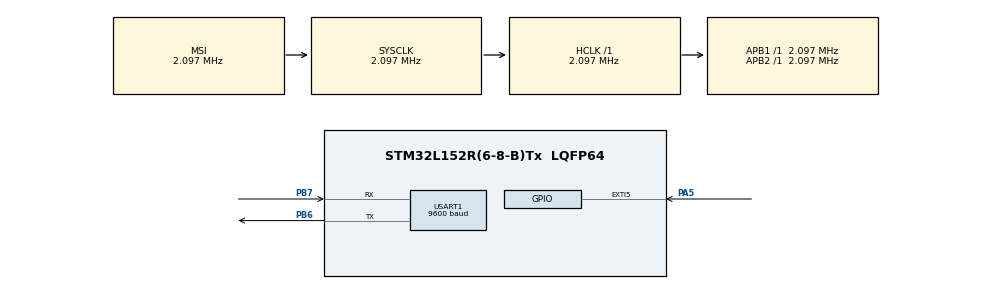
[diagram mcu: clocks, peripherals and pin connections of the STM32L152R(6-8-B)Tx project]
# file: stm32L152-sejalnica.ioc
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Mcu.Family=STM32L1
Mcu.Name=STM32L152R(6-8-B)Tx
Mcu.Package=LQFP64
NVIC.EXTI9_5_IRQn=true\:0\:0\:false\:false\:true\:true
NVIC.PriorityGroup=NVIC_PRIORITYGROUP_4
NVIC.TIM2_IRQn=true\:0\:0\:false\:false\:true\:true
NVIC.USART1_IRQn=true\:0\:0\:false\:false\:true\:true
PA5.GPIO_PuPd=GPIO_PULLUP
PA5.Signal=GPXTI5
PB6.Mode=Asynchronous
PB6.Signal=USART1_TX
PB7.Mode=Asynchronous
PB7.Signal=USART1_RX
ProjectManager.HeapSize=0x200
ProjectManager.StackSize=0x400
ProjectManager.TargetToolchain=SW4STM32
RCC.AHBFreq_Value=2097000
RCC.APB1Freq_Value=2097000
RCC.APB2Freq_Value=2097000
RCC.HSE_VALUE=24000000
RCC.HSI_VALUE=16000000
RCC.LSE_VALUE=32768
RCC.MSI_VALUE=2097000
RCC.SYSCLKFreq_VALUE=2097000
RCC.VCOOutputFreq_Value=48000000
TIM2.Period=5999
TIM2.Prescaler=20970
USART1.BaudRate=9600
USART1.VirtualMode=VM_ASYNC
VP_TIM2_VS_ClockSourceINT.Mode=Internal
board=stm32L152-sejalnica

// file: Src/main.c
/**
  ******************************************************************************
  * File Name          : main.c
  * Description        : Main program body
  ******************************************************************************
  *
  * COPYRIGHT(c) 2017 STMicroelectronics
  *
  * Redistribution and use in source and binary forms, with or without modification,
  * are permitted provided that the following conditions are met:
  *   1. Redistributions of source code must retain the above copyright notice,
  *      this list of conditions and the following disclaimer.
  *   2. Redistributions in binary form must reproduce the above copyright notice,
  *      this list of conditions and the following disclaimer in the documentation
  *      and/or other materials provided with the distribution.
  *   3. Neither the name of STMicroelectronics nor the names of its contributors
  *      may be used to endorse or promote products derived from this software
  *      without specific prior written permission.
  *
  * THIS SOFTWARE IS PROVIDED BY THE COPYRIGHT HOLDERS AND CONTRIBUTORS "AS IS"
  * AND ANY EXPRESS OR IMPLIED WARRANTIES, INCLUDING, BUT NOT LIMITED TO, THE
  * IMPLIED WARRANTIES OF MERCHANTABILITY AND FITNESS FOR A PARTICULAR PURPOSE ARE
  * DISCLAIMED. IN NO EVENT SHALL THE COPYRIGHT HOLDER OR CONTRIBUTORS BE LIABLE
  * FOR ANY DIRECT, INDIRECT, INCIDENTAL, SPECIAL, EXEMPLARY, OR CONSEQUENTIAL
  * DAMAGES (INCLUDING, BUT NOT LIMITED TO, PROCUREMENT OF SUBSTITUTE GOODS OR
  * SERVICES; LOSS OF USE, DATA, OR PROFITS; OR BUSINESS INTERRUPTION) HOWEVER
  * CAUSED AND ON ANY THEORY OF LIABILITY, WHETHER IN CONTRACT, STRICT LIABILITY,
  * OR TORT (INCLUDING NEGLIGENCE OR OTHERWISE) ARISING IN ANY WAY OUT OF THE USE
  * OF THIS SOFTWARE, EVEN IF ADVISED OF THE POSSIBILITY OF SUCH DAMAGE.
  *
  ******************************************************************************
  */
#include "main.h"
#include "stm32l1xx_hal.h"

/* USER CODE BEGIN Includes */
#include "stm32l152c_discovery.h"
#include "stm32l152c_discovery_glass_lcd.h"

/* USER CODE END Includes */

TIM_HandleTypeDef htim2;

UART_HandleTypeDef huart1;

/* USER CODE BEGIN PV */
/* Private variables ---------------------------------------------------------*/
int stevec=0;
int cas=0;
char data_tx[10];
char data_rx[2];
int len;
int overflow=0;
float sirina=3.0;//3=sirina sejalnice
float obseg;
float povrsina;
char* stevka_tmp;
char lcd_text[6];
/* USER CODE END PV */

void SystemClock_Config(void);
void Error_Handler(void);
static void MX_GPIO_Init(void);
static void MX_TIM2_Init(void);
static void MX_USART1_UART_Init(void);

/* USER CODE BEGIN PFP */
/* Private function prototypes -----------------------------------------------*/

char *substring(int i,int j,char *ch)
{
    int n,k=0;
    char *ch1;
    ch1=(char*)malloc((j-i+1)*1);
    n=j-i+1;

    while(k<n)
    {
        ch1[k]=ch[i];
        i++;k++;
    }
    return (char *)ch1;
}

float area(int counter){
		return (float)counter/4100;
}

float speed(float time, float circum){
  return (float)(circum/time)*1000;
}

void display(int counter, int mode){
	if (counter<50){
		sprintf(lcd_text, "%d",counter);
		BSP_LCD_GLASS_Clear();
		BSP_LCD_GLASS_DisplayString((uint8_t*)lcd_text);
	}
	else{
		if( counter%5 == 0 ){
		      sprintf(lcd_text, "%2.3f",area(counter));
		      BSP_LCD_GLASS_Clear();
		      BSP_LCD_GLASS_DisplayString((uint8_t*)lcd_text);
		}
		if (mode==1){
		      sprintf(lcd_text, "%2.3f",area(counter));
		      BSP_LCD_GLASS_Clear();
		      BSP_LCD_GLASS_DisplayString((uint8_t*)lcd_text);
		}
	}
	return;
}

void send_uart(int counter, int time){
	if (counter<50){
		if (time==0){
			sprintf(data_tx, "#%d-0~",stevec);
		}
		else{
			sprintf(data_tx, "#%d-%2.1f~",stevec, speed((float)time, obseg));
		}
	}
	else{
		if (time==0){
			sprintf(data_tx, "#%.4f-0~",area(stevec));
		}
		else{
			sprintf(data_tx, "#%.4f-%2.1f~",area(stevec), speed((float)time, obseg));
		}
	}
	len=strlen(data_tx);
	HAL_UART_Transmit( &huart1, data_tx, len, 100);
	return;

}

//ineruptna rutina za 'magnetni' stik na A5-GND
void HAL_GPIO_EXTI_Callback(uint16_t GPIO_Pin){
	stevec++;
  if (overflow!=0){
    cas=0;
    overflow=0;
  }
  else{
    cas = TIM2->CNT;
  }
  TIM2->CNT=0;

  send_uart(stevec,cas);
  display(stevec,0);
}

  /**
* @brief This function handles TIM2 global interrupt.
*/
void TIM2_IRQHandler(void)
{
  /* USER CODE BEGIN TIM2_IRQn 0 */

  TIM2->SR &=~TIM_SR_UIF;
  overflow++;
  send_uart(stevec,0);
  display(stevec,0);

  /* USER CODE END TIM2_IRQn 0 */
  //HAL_TIM_IRQHandler(&htim2);
  /* USER CODE BEGIN TIM2_IRQn 1 */

  /* USER CODE END TIM2_IRQn 1 */
}

//variables need to be declared at the beginning for USART
char Rx_indx, Rx_data[6], Rx_Buffer[20], Transfer_cplt;
int vred;
//Interrupt callback routine for USART receive

void HAL_UART_RxCpltCallback(UART_HandleTypeDef *huart)
{
	uint8_t i;
	if (huart->Instance == USART1)	//current UART
		{
		if (Rx_indx==0) {for (i=0;i<20;i++) Rx_Buffer[i]=0;}	//clear Rx_Buffer before receiving new data
                  if (Rx_data[0]!=33)	//if received data different from ascii 33 (!)
                          {
                          Rx_Buffer[Rx_indx++]=Rx_data[0];	//add data to Rx_Buffer

                          }
                  else			//if received data = 13
                          {
                          Rx_indx=0;
                          Transfer_cplt=1;//transfer complete, data is ready to read
                          if (Rx_Buffer[0]==35) //35=#=nastavljanje dolzine
                          {
                            stevka_tmp=substring(1,sizeof(Rx_Buffer),Rx_Buffer);
                            stevec=atoi(stevka_tmp);
                            sprintf(data_tx, "-%d~",stevec);
                            len=strlen(data_tx);
                            HAL_UART_Transmit( &huart1, (uint8_t*)data_tx , len, 100);
                            }

                          if (Rx_Buffer[0]==36) //36=$=refresh button
                          {
                            display(stevec,1);
                            send_uart(stevec,0);
                            }
                          }
                  HAL_UART_Receive_IT(&huart1, Rx_data, 1);	//activate UART receive interrupt every time
		}

}
/* USER CODE END PFP */

int main(void)
{

  /* USER CODE BEGIN 1 */
	obseg=100/41/sirina;
  /* USER CODE END 1 */

  /* MCU Configuration----------------------------------------------------------*/

  /* Reset of all peripherals, Initializes the Flash interface and the Systick. */
  HAL_Init();

  /* Configure the system clock */
  SystemClock_Config();

  /* Initialize all configured peripherals */
  //A5-GND
  MX_GPIO_Init();

  MX_TIM2_Init();
  /* pomen pinov na plosci:
  TX:B6
  RX:B7
  povezava na companion device:
  tx->B7
  rx->B6
  */
  MX_USART1_UART_Init();

  BSP_LCD_GLASS_Init();

  /* USER CODE BEGIN 2 */
  HAL_TIM_Base_Start_IT(&htim2); //zaceek interupta za timer
  TIM2->CR1 |= 0x0001;

  HAL_UART_Receive_IT(&huart1, (uint8_t*)Rx_data, 1); //start inerupta za uart
  /* USER CODE END 2 */

  /* Infinite loop */
   while (1)
  {

  }

}

/** System Clock Configuration
*/
void SystemClock_Config(void)
{

  RCC_OscInitTypeDef RCC_OscInitStruct;
  RCC_ClkInitTypeDef RCC_ClkInitStruct;

    /**Configure the main internal regulator output voltage
    */
  __HAL_PWR_VOLTAGESCALING_CONFIG(PWR_REGULATOR_VOLTAGE_SCALE1);

    /**Initializes the CPU, AHB and APB busses clocks
    */
  RCC_OscInitStruct.OscillatorType = RCC_OSCILLATORTYPE_MSI;
  RCC_OscInitStruct.MSIState = RCC_MSI_ON;
  RCC_OscInitStruct.MSICalibrationValue = 0;
  RCC_OscInitStruct.MSIClockRange = RCC_MSIRANGE_5;
  RCC_OscInitStruct.PLL.PLLState = RCC_PLL_NONE;
  if (HAL_RCC_OscConfig(&RCC_OscInitStruct) != HAL_OK)
  {
    Error_Handler();
  }

    /**Initializes the CPU, AHB and APB busses clocks
    */
  RCC_ClkInitStruct.ClockType = RCC_CLOCKTYPE_HCLK|RCC_CLOCKTYPE_SYSCLK
                              |RCC_CLOCKTYPE_PCLK1|RCC_CLOCKTYPE_PCLK2;
  RCC_ClkInitStruct.SYSCLKSource = RCC_SYSCLKSOURCE_MSI;
  RCC_ClkInitStruct.AHBCLKDivider = RCC_SYSCLK_DIV1;
  RCC_ClkInitStruct.APB1CLKDivider = RCC_HCLK_DIV1;
  RCC_ClkInitStruct.APB2CLKDivider = RCC_HCLK_DIV1;

  if (HAL_RCC_ClockConfig(&RCC_ClkInitStruct, FLASH_LATENCY_0) != HAL_OK)
  {
    Error_Handler();
  }

    /**Configure the Systick interrupt time
    */
  HAL_SYSTICK_Config(HAL_RCC_GetHCLKFreq()/1000);

    /**Configure the Systick
    */
  HAL_SYSTICK_CLKSourceConfig(SYSTICK_CLKSOURCE_HCLK);

  /* SysTick_IRQn interrupt configuration */
  HAL_NVIC_SetPriority(SysTick_IRQn, 0, 0);
}

/* TIM2 init function */
static void MX_TIM2_Init(void)
{

  TIM_ClockConfigTypeDef sClockSourceConfig;
  TIM_MasterConfigTypeDef sMasterConfig;

  htim2.Instance = TIM2;
  htim2.Init.Prescaler = 2097;
  htim2.Init.CounterMode = TIM_COUNTERMODE_UP;
  htim2.Init.Period = 999; //stevilo sekund (ms!!!!), da se hitrost spravi na 0, po ustavitvi
  htim2.Init.ClockDivision = TIM_CLOCKDIVISION_DIV1;
  if (HAL_TIM_Base_Init(&htim2) != HAL_OK)
  {
    Error_Handler();
  }

  sClockSourceConfig.ClockSource = TIM_CLOCKSOURCE_INTERNAL;
  if (HAL_TIM_ConfigClockSource(&htim2, &sClockSourceConfig) != HAL_OK)
  {
    Error_Handler();
  }

  sMasterConfig.MasterOutputTrigger = TIM_TRGO_RESET;
  sMasterConfig.MasterSlaveMode = TIM_MASTERSLAVEMODE_DISABLE;
  if (HAL_TIMEx_MasterConfigSynchronization(&htim2, &sMasterConfig) != HAL_OK)
  {
    Error_Handler();
  }

}

/* USART1 init function */
static void MX_USART1_UART_Init(void)
{

  huart1.Instance = USART1;
  huart1.Init.BaudRate = 9600;
  huart1.Init.WordLength = UART_WORDLENGTH_8B;
  huart1.Init.StopBits = UART_STOPBITS_1;
  huart1.Init.Parity = UART_PARITY_NONE;
  huart1.Init.Mode = UART_MODE_TX_RX;
  huart1.Init.HwFlowCtl = UART_HWCONTROL_NONE;
  huart1.Init.OverSampling = UART_OVERSAMPLING_16;
  if (HAL_UART_Init(&huart1) != HAL_OK)
  {
    Error_Handler();
  }

}

/** Configure pins as
        * Analog
        * Input
        * Output
        * EVENT_OUT
        * EXTI
*/
static void MX_GPIO_Init(void)
{

  GPIO_InitTypeDef GPIO_InitStruct;

  /* GPIO Ports Clock Enable */
  __HAL_RCC_GPIOA_CLK_ENABLE();
  __HAL_RCC_GPIOB_CLK_ENABLE();

  /*Configure GPIO pin : PA5 */
  GPIO_InitStruct.Pin = GPIO_PIN_5;
  GPIO_InitStruct.Mode = GPIO_MODE_IT_RISING;
  GPIO_InitStruct.Pull = GPIO_PULLUP;
  HAL_GPIO_Init(GPIOA, &GPIO_InitStruct);

  /* EXTI interrupt init*/
  HAL_NVIC_SetPriority(EXTI9_5_IRQn, 0, 0);
  HAL_NVIC_EnableIRQ(EXTI9_5_IRQn);

}

void Error_Handler(void)
{
  while(1)
  {
  }
}

/************************ (C) COPYRIGHT STMicroelectronics *****END OF FILE****/
